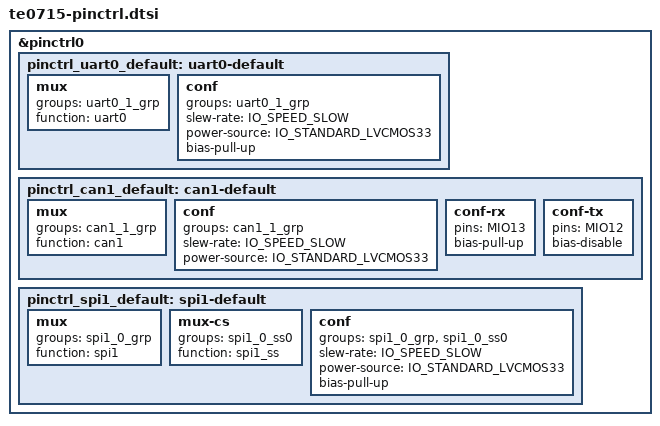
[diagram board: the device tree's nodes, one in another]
/*
 * Pin configuration for the Trenz TE0715, matching the PS settings of the
 * Trenz TE0715 test_board reference design (Vivado 2022.2).
 */

#include <zephyr/dt-bindings/pinctrl/pinctrl-zynq.h>

&pinctrl0 {
	/* UART0 on MIO14 (RX) / MIO15 (TX), bank 0 is LVCMOS 3.3V */
	pinctrl_uart0_default: uart0-default {
		mux {
			groups = "uart0_1_grp";
			function = "uart0";
		};

		conf {
			groups = "uart0_1_grp";
			slew-rate = <IO_SPEED_SLOW>;
			power-source = <IO_STANDARD_LVCMOS33>;
			bias-pull-up;
		};
	};

	/* CAN1 on MIO12 (TX) / MIO13 (RX) */
	pinctrl_can1_default: can1-default {
		mux {
			groups = "can1_1_grp";
			function = "can1";
		};

		conf {
			groups = "can1_1_grp";
			slew-rate = <IO_SPEED_SLOW>;
			power-source = <IO_STANDARD_LVCMOS33>;
		};

		conf-rx {
			pins = "MIO13";
			bias-pull-up;
		};

		conf-tx {
			pins = "MIO12";
			bias-disable;
		};
	};

	/*
	 * SPI1 on MIO10 (MOSI), MIO11 (MISO) and MIO12 (SCLK), with its own slave select
	 * SS0 on MIO13 as the chip select. SS0 must be on a pin: in master mode the
	 * controller does not start a transfer while its SS0 input is low, and without
	 * the pin that input comes from the PL, where it is low in the reference design.
	 * A GPIO chip select on MIO13 therefore cannot work. The same pins as CAN1 on
	 * MIO12/13: an application enables either spi1 or can1. MISO keeps its pull-up, so
	 * an unconnected sensor reads as all ones rather than as floating data.
	 */
	pinctrl_spi1_default: spi1-default {
		mux {
			groups = "spi1_0_grp";
			function = "spi1";
		};

		mux-cs {
			groups = "spi1_0_ss0";
			function = "spi1_ss";
		};

		conf {
			groups = "spi1_0_grp", "spi1_0_ss0";
			slew-rate = <IO_SPEED_SLOW>;
			power-source = <IO_STANDARD_LVCMOS33>;
			bias-pull-up;
		};
	};
};
